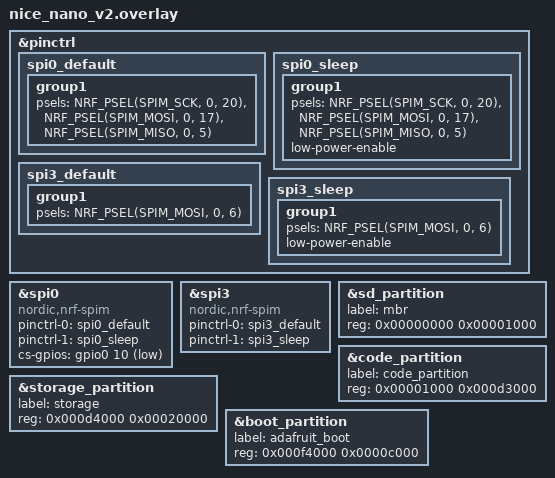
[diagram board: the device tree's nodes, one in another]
&pinctrl {
    spi0_default: spi0_default {
        group1 {
            psels = <NRF_PSEL(SPIM_SCK, 0, 20)>,
                <NRF_PSEL(SPIM_MOSI, 0, 17)>,
                <NRF_PSEL(SPIM_MISO, 0, 5)>;
        };
    };

    spi0_sleep: spi0_sleep {
        group1 {
            psels = <NRF_PSEL(SPIM_SCK, 0, 20)>,
                <NRF_PSEL(SPIM_MOSI, 0, 17)>,
                <NRF_PSEL(SPIM_MISO, 0, 5)>;
            low-power-enable;
        };
    };

    spi3_default: spi3_default {
        group1 {
            psels = <NRF_PSEL(SPIM_MOSI, 0, 6)>; // WS2812_VEXT_DATA
        };
    };

    spi3_sleep: spi3_sleep {
        group1 {
            psels = <NRF_PSEL(SPIM_MOSI, 0, 6)>;
            low-power-enable;
        };
    };
};

&spi0 {
    status = "okay";
    compatible = "nordic,nrf-spim";
    pinctrl-0 = <&spi0_default>;
    pinctrl-1 = <&spi0_sleep>;
    pinctrl-names = "default", "sleep";
    cs-gpios = <&gpio0 10 GPIO_ACTIVE_LOW>;
};

&spi3 {
    compatible = "nordic,nrf-spim";
    status = "okay";

    pinctrl-0 = <&spi3_default>;
    pinctrl-1 = <&spi3_sleep>;
    pinctrl-names = "default", "sleep";
};

&sd_partition {
    label = "mbr";
    reg = <0x00000000 0x00001000>;
};

&code_partition {
    label = "code_partition";
    reg = <0x00001000 0x000d3000>;
};

&storage_partition {
    label = "storage";
    reg = <0x000d4000 0x00020000>;
};

&boot_partition {
    label = "adafruit_boot";
    reg = <0x000f4000 0x0000c000>;
};
